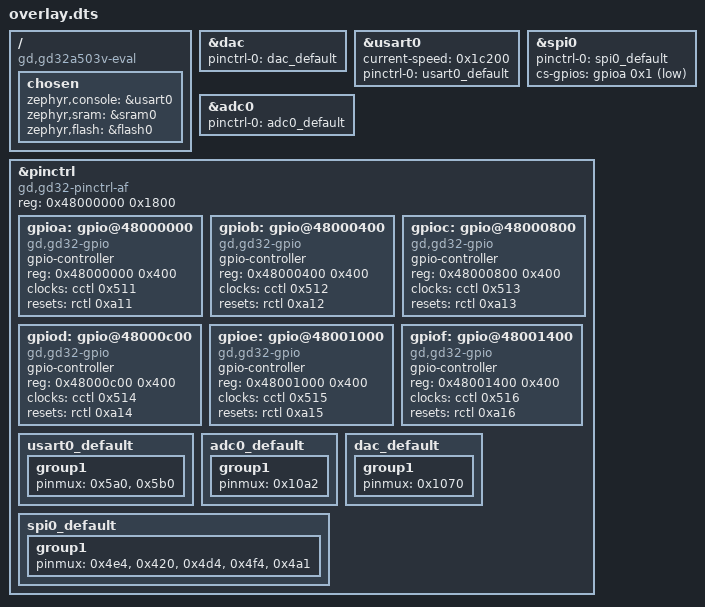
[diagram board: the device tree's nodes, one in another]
/ {
	compatible = "gd,gd32a503v-eval";
	chosen {
		zephyr,console = &usart0;
		zephyr,sram = &sram0;
		zephyr,flash = &flash0;
	};
};
&gpiod{
	status = "okay";
};
&gpiof{
	status = "okay";
};
&dac{
	status = "okay";
	pinctrl-0 = < &dac_default >;
	pinctrl-names = "default";
};
&gpioe{
	status = "okay";
};
&usart0{
	status = "okay";
	current-speed = < 0x1c200 >;
	pinctrl-0 = < &usart0_default >;
	pinctrl-names = "default";
};
&spi0{
	status = "okay";
	pinctrl-0 = < &spi0_default >;
	pinctrl-names = "default";
	cs-gpios = < &gpioa 0x1 0x1 >;
};
&gpioc{
	status = "okay";
};
&adc0{
	status = "okay";
	pinctrl-0 = < &adc0_default >;
	pinctrl-names = "default";
};
&gpioa{
	status = "okay";
};
&gpiob{
	status = "okay";
};
&pinctrl{
	compatible = "gd,gd32-pinctrl-af";
	reg = < 0x48000000 0x1800 >;
	#address-cells = < 0x1 >;
	#size-cells = < 0x1 >;
	status = "okay";
	gpioa: gpio@48000000 {
		compatible = "gd,gd32-gpio";
		gpio-controller;
		#gpio-cells = < 0x2 >;
		reg = < 0x48000000 0x400 >;
		clocks = < &cctl 0x511 >;
		resets = < &rctl 0xa11 >;
		status = "okay";
	};
	gpiob: gpio@48000400 {
		compatible = "gd,gd32-gpio";
		gpio-controller;
		#gpio-cells = < 0x2 >;
		reg = < 0x48000400 0x400 >;
		clocks = < &cctl 0x512 >;
		resets = < &rctl 0xa12 >;
		status = "okay";
	};
	gpioc: gpio@48000800 {
		compatible = "gd,gd32-gpio";
		gpio-controller;
		#gpio-cells = < 0x2 >;
		reg = < 0x48000800 0x400 >;
		clocks = < &cctl 0x513 >;
		resets = < &rctl 0xa13 >;
		status = "okay";
	};
	gpiod: gpio@48000c00 {
		compatible = "gd,gd32-gpio";
		gpio-controller;
		#gpio-cells = < 0x2 >;
		reg = < 0x48000c00 0x400 >;
		clocks = < &cctl 0x514 >;
		resets = < &rctl 0xa14 >;
		status = "okay";
	};
	gpioe: gpio@48001000 {
		compatible = "gd,gd32-gpio";
		gpio-controller;
		#gpio-cells = < 0x2 >;
		reg = < 0x48001000 0x400 >;
		clocks = < &cctl 0x515 >;
		resets = < &rctl 0xa15 >;
		status = "okay";
	};
	gpiof: gpio@48001400 {
		compatible = "gd,gd32-gpio";
		gpio-controller;
		#gpio-cells = < 0x2 >;
		reg = < 0x48001400 0x400 >;
		clocks = < &cctl 0x516 >;
		resets = < &rctl 0xa16 >;
		status = "okay";
	};
	usart0_default: usart0_default {
		group1 {
			pinmux = < 0x5a0 >, < 0x5b0 >;
		};
	};
	adc0_default: adc0_default {
		group1 {
			pinmux = < 0x10a2 >;
		};
	};
	dac_default: dac_default {
		group1 {
			pinmux = < 0x1070 >;
		};
	};
	spi0_default: spi0_default {
		group1 {
			pinmux = < 0x4e4 >, < 0x420 >, < 0x4d4 >, < 0x4f4 >, < 0x4a1 >;
		};
	};
};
